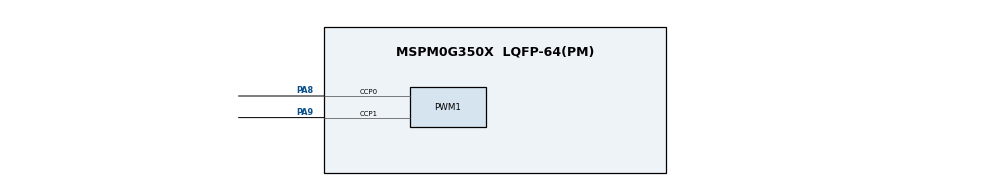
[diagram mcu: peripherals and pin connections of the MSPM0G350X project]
/**
 * @cliArgs --device "MSPM0G350X" --part "Default" --package "LQFP-64(PM)" --product "mspm0_sdk@2.04.00.06"
 * @versions {"tool":"1.23.1+4034"}
 */

/**
 * Import the modules used in this configuration.
 */
const GPIO   = scripting.addModule("/ti/driverlib/GPIO", {}, false);
const GPIO1  = GPIO.addInstance();
const GPIO2  = GPIO.addInstance();
const GPIO3  = GPIO.addInstance();
const GPIO4  = GPIO.addInstance();
const GPIO5  = GPIO.addInstance();
const PWM    = scripting.addModule("/ti/driverlib/PWM", {}, false);
const PWM1   = PWM.addInstance();
const SYSCTL = scripting.addModule("/ti/driverlib/SYSCTL");
const TIMER  = scripting.addModule("/ti/driverlib/TIMER", {}, false);
const TIMER1 = TIMER.addInstance();

/**
 * Write custom configuration values to the imported modules.
 */
GPIO1.$name                         = "GPIO_MOTOR_LEFT";
GPIO1.port                          = "PORTA";
GPIO1.associatedPins.create(2);
GPIO1.associatedPins[0].ioStructure = "SD";
GPIO1.associatedPins[0].assignedPin = "26";
GPIO1.associatedPins[0].$name       = "PINA_26";
GPIO1.associatedPins[1].$name       = "PINA_27";
GPIO1.associatedPins[1].ioStructure = "SD";
GPIO1.associatedPins[1].assignedPin = "27";

const Board = scripting.addModule("/ti/driverlib/Board", {}, false);

GPIO2.$name                         = "GPIO_MOTOR_RIGHT";
GPIO2.port                          = "PORTA";
GPIO2.associatedPins.create(2);
GPIO2.associatedPins[0].ioStructure = "SD";
GPIO2.associatedPins[0].assignedPin = "24";
GPIO2.associatedPins[0].$name       = "PINA_24";
GPIO2.associatedPins[1].ioStructure = "SD";
GPIO2.associatedPins[1].$name       = "PINA_25";
GPIO2.associatedPins[1].assignedPin = "25";

GPIO3.$name                               = "GPIO_READ";
GPIO3.associatedPins.create(12);
GPIO3.associatedPins[0].direction         = "INPUT";
GPIO3.associatedPins[0].ioStructure       = "SD";
GPIO3.associatedPins[0].assignedPort      = "PORTA";
GPIO3.associatedPins[0].assignedPin       = "15";
GPIO3.associatedPins[0].$name             = "PINA_15";
GPIO3.associatedPins[0].internalResistor  = "PULL_UP";
GPIO3.associatedPins[1].$name             = "PINA_16";
GPIO3.associatedPins[1].direction         = "INPUT";
GPIO3.associatedPins[1].ioStructure       = "SD";
GPIO3.associatedPins[1].assignedPort      = "PORTA";
GPIO3.associatedPins[1].assignedPin       = "16";
GPIO3.associatedPins[1].internalResistor  = "PULL_UP";
GPIO3.associatedPins[2].direction         = "INPUT";
GPIO3.associatedPins[2].ioStructure       = "SD";
GPIO3.associatedPins[2].assignedPin       = "18";
GPIO3.associatedPins[2].assignedPort      = "PORTB";
GPIO3.associatedPins[2].$name             = "PINB_18";
GPIO3.associatedPins[2].internalResistor  = "PULL_UP";
GPIO3.associatedPins[3].assignedPin       = "19";
GPIO3.associatedPins[3].assignedPort      = "PORTB";
GPIO3.associatedPins[3].direction         = "INPUT";
GPIO3.associatedPins[3].ioStructure       = "SD";
GPIO3.associatedPins[3].$name             = "PINB_19";
GPIO3.associatedPins[3].internalResistor  = "PULL_UP";
GPIO3.associatedPins[4].assignedPin       = "21";
GPIO3.associatedPins[4].assignedPort      = "PORTA";
GPIO3.associatedPins[4].direction         = "INPUT";
GPIO3.associatedPins[4].$name             = "PINA_21";
GPIO3.associatedPins[4].ioStructure       = "SD";
GPIO3.associatedPins[4].internalResistor  = "PULL_UP";
GPIO3.associatedPins[5].assignedPin       = "22";
GPIO3.associatedPins[5].assignedPort      = "PORTA";
GPIO3.associatedPins[5].direction         = "INPUT";
GPIO3.associatedPins[5].$name             = "PINA_22";
GPIO3.associatedPins[5].ioStructure       = "SD";
GPIO3.associatedPins[5].internalResistor  = "PULL_UP";
GPIO3.associatedPins[6].assignedPin       = "20";
GPIO3.associatedPins[6].assignedPort      = "PORTB";
GPIO3.associatedPins[6].direction         = "INPUT";
GPIO3.associatedPins[6].ioStructure       = "SD";
GPIO3.associatedPins[6].$name             = "PINB_20";
GPIO3.associatedPins[6].internalResistor  = "PULL_UP";
GPIO3.associatedPins[7].direction         = "INPUT";
GPIO3.associatedPins[7].assignedPin       = "24";
GPIO3.associatedPins[7].assignedPort      = "PORTB";
GPIO3.associatedPins[7].$name             = "PINB_24";
GPIO3.associatedPins[7].ioStructure       = "SD";
GPIO3.associatedPins[7].internalResistor  = "PULL_UP";
GPIO3.associatedPins[8].direction         = "INPUT";
GPIO3.associatedPins[8].ioStructure       = "SD";
GPIO3.associatedPins[8].assignedPort      = "PORTA";
GPIO3.associatedPins[8].assignedPin       = "23";
GPIO3.associatedPins[8].$name             = "PINA_23";
GPIO3.associatedPins[8].internalResistor  = "PULL_UP";
GPIO3.associatedPins[9].direction         = "INPUT";
GPIO3.associatedPins[9].ioStructure       = "SD";
GPIO3.associatedPins[9].assignedPin       = "9";
GPIO3.associatedPins[9].assignedPort      = "PORTB";
GPIO3.associatedPins[9].$name             = "PINB_9";
GPIO3.associatedPins[9].internalResistor  = "PULL_UP";
GPIO3.associatedPins[10].assignedPort     = "PORTB";
GPIO3.associatedPins[10].direction        = "INPUT";
GPIO3.associatedPins[10].assignedPin      = "8";
GPIO3.associatedPins[10].$name            = "PINB_8";
GPIO3.associatedPins[10].ioStructure      = "SD";
GPIO3.associatedPins[10].internalResistor = "PULL_UP";
GPIO3.associatedPins[11].direction        = "INPUT";
GPIO3.associatedPins[11].ioStructure      = "SD";
GPIO3.associatedPins[11].assignedPort     = "PORTB";
GPIO3.associatedPins[11].assignedPin      = "7";
GPIO3.associatedPins[11].$name            = "PINB_7";
GPIO3.associatedPins[11].internalResistor = "PULL_UP";

GPIO4.$name                              = "GPIO_KEY";
GPIO4.associatedPins.create(2);
GPIO4.associatedPins[0].direction        = "INPUT";
GPIO4.associatedPins[0].ioStructure      = "SD";
GPIO4.associatedPins[0].internalResistor = "PULL_UP";
GPIO4.associatedPins[0].$name            = "PINB_6";
GPIO4.associatedPins[0].assignedPin      = "6";
GPIO4.associatedPins[0].assignedPort     = "PORTB";
GPIO4.associatedPins[1].ioStructure      = "SD";
GPIO4.associatedPins[1].assignedPort     = "PORTA";
GPIO4.associatedPins[1].assignedPin      = "2";
GPIO4.associatedPins[1].$name            = "PINA_2";
GPIO4.associatedPins[1].direction        = "INPUT";
GPIO4.associatedPins[1].internalResistor = "PULL_UP";

GPIO5.$name                          = "GPIO_SOUND";
GPIO5.associatedPins[0].ioStructure  = "SD";
GPIO5.associatedPins[0].assignedPort = "PORTB";
GPIO5.associatedPins[0].assignedPin  = "2";
GPIO5.associatedPins[0].$name        = "PINB_2";
GPIO5.associatedPins[0].initialValue = "SET";

PWM1.$name                              = "PWM_MOTOR";
PWM1.clockPrescale                      = 2;
PWM1.timerCount                         = 800;
PWM1.pwmMode                            = "EDGE_ALIGN_UP";
PWM1.peripheral.$assign                 = "TIMA0";
PWM1.peripheral.ccp0Pin.$assign         = "PA8";
PWM1.peripheral.ccp1Pin.$assign         = "PA9";
PWM1.PWM_CHANNEL_0.$name                = "ti_driverlib_pwm_PWMTimerCC0";
PWM1.PWM_CHANNEL_1.$name                = "ti_driverlib_pwm_PWMTimerCC1";
PWM1.ccp0PinConfig.$name                = "ti_driverlib_gpio_GPIOPinGeneric0";
PWM1.ccp0PinConfig.direction            = scripting.forceWrite("OUTPUT");
PWM1.ccp0PinConfig.hideOutputInversion  = scripting.forceWrite(false);
PWM1.ccp0PinConfig.onlyInternalResistor = scripting.forceWrite(false);
PWM1.ccp0PinConfig.passedPeripheralType = scripting.forceWrite("Digital");
PWM1.ccp1PinConfig.$name                = "ti_driverlib_gpio_GPIOPinGeneric1";
PWM1.ccp1PinConfig.direction            = scripting.forceWrite("OUTPUT");
PWM1.ccp1PinConfig.hideOutputInversion  = scripting.forceWrite(false);
PWM1.ccp1PinConfig.onlyInternalResistor = scripting.forceWrite(false);
PWM1.ccp1PinConfig.passedPeripheralType = scripting.forceWrite("Digital");

SYSCTL.forceDefaultClkConfig = true;

TIMER1.timerClkDiv      = 8;
TIMER1.timerClkPrescale = 200;
TIMER1.timerMode        = "PERIODIC_UP";
TIMER1.timerStartTimer  = true;
TIMER1.interrupts       = ["ZERO"];
TIMER1.timerPeriod      = "10 ms";
TIMER1.$name            = "TIMER_10ms";

/**
 * Pinmux solution for unlocked pins/peripherals. This ensures that minor changes to the automatic solver in a future
 * version of the tool will not impact the pinmux you originally saw.  These lines can be completely deleted in order to
 * re-solve from scratch.
 */
GPIO1.associatedPins[0].pin.$suggestSolution  = "PA26";
GPIO1.associatedPins[1].pin.$suggestSolution  = "PA27";
Board.peripheral.$suggestSolution             = "DEBUGSS";
Board.peripheral.swclkPin.$suggestSolution    = "PA20";
Board.peripheral.swdioPin.$suggestSolution    = "PA19";
GPIO2.associatedPins[0].pin.$suggestSolution  = "PA24";
GPIO2.associatedPins[1].pin.$suggestSolution  = "PA25";
GPIO3.associatedPins[0].pin.$suggestSolution  = "PA15";
GPIO3.associatedPins[1].pin.$suggestSolution  = "PA16";
GPIO3.associatedPins[2].pin.$suggestSolution  = "PB18";
GPIO3.associatedPins[3].pin.$suggestSolution  = "PB19";
GPIO3.associatedPins[4].pin.$suggestSolution  = "PA21";
GPIO3.associatedPins[5].pin.$suggestSolution  = "PA22";
GPIO3.associatedPins[6].pin.$suggestSolution  = "PB20";
GPIO3.associatedPins[7].pin.$suggestSolution  = "PB24";
GPIO3.associatedPins[8].pin.$suggestSolution  = "PA23";
GPIO3.associatedPins[9].pin.$suggestSolution  = "PB9";
GPIO3.associatedPins[10].pin.$suggestSolution = "PB8";
GPIO3.associatedPins[11].pin.$suggestSolution = "PB7";
GPIO4.associatedPins[0].pin.$suggestSolution  = "PB6";
GPIO4.associatedPins[1].pin.$suggestSolution  = "PA2";
GPIO5.associatedPins[0].pin.$suggestSolution  = "PB2";
SYSCTL.peripheral.$suggestSolution            = "SYSCTL";
TIMER1.peripheral.$suggestSolution            = "TIMA1";
